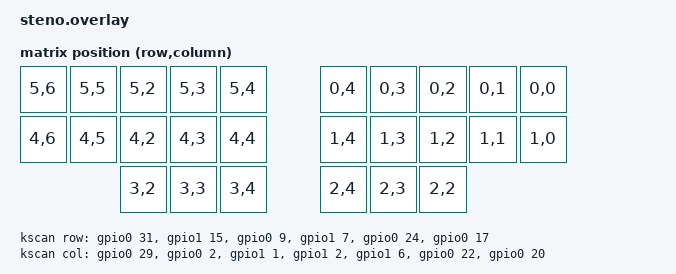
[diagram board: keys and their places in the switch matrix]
// This file was generated from a template. Edit it to match your keyboard.
// See https://zmk.dev/docs/development/hardware-integration/new-shield for more
// instructions.

#include <dt-bindings/zmk/matrix_transform.h>

#include "steno-layouts.dtsi"

/ {
    chosen {
        zmk,physical-layout = &default_layout;
    };

    kscan: kscan {
        // If the hardware does not use a switch matrix, change this to the
        // appropriate driver and update the properties below to match.
        // See https://zmk.dev/docs/config/kscan for supported key scan drivers.
        compatible = "zmk,kscan-gpio-matrix";
        // Set this to "col2row" or "row2col" to match the hardware. If using
        // "row2col", change the col-gpios to (GPIO_ACTIVE_HIGH | GPIO_PULL_DOWN)
        // and the row-gpios to GPIO_ACTIVE_HIGH.
        diode-direction = "col2row";
        wakeup-source;

        // Replace these comments with the GPIO pins in the matrix.
        // See https://zmk.dev/docs/development/hardware-integration/new-shield#shield-overlays
        col-gpios
            = <&gpio0 29 GPIO_ACTIVE_HIGH>
            , <&gpio0 2 GPIO_ACTIVE_HIGH>
            , <&gpio1 1 GPIO_ACTIVE_HIGH>
            , <&gpio1 2 GPIO_ACTIVE_HIGH>
            , <&gpio1 6 GPIO_ACTIVE_HIGH>
            , <&gpio0 22 GPIO_ACTIVE_HIGH>
            , <&gpio0 20 GPIO_ACTIVE_HIGH>
            ;

        row-gpios
            = <&gpio0 31 (GPIO_ACTIVE_HIGH | GPIO_PULL_DOWN)>
            , <&gpio1 15 (GPIO_ACTIVE_HIGH | GPIO_PULL_DOWN)>
            , <&gpio0 9 (GPIO_ACTIVE_HIGH | GPIO_PULL_DOWN)>
            , <&gpio1 7 (GPIO_ACTIVE_HIGH | GPIO_PULL_DOWN)>
            , <&gpio0 24 (GPIO_ACTIVE_HIGH | GPIO_PULL_DOWN)>
            , <&gpio0 17 (GPIO_ACTIVE_HIGH | GPIO_PULL_DOWN)>
            ;
    };

    default_transform: default_transform {
        // See https://zmk.dev/docs/development/hardware-integration/new-shield#matrix-transform
        // for how to configure this
        compatible = "zmk,matrix-transform";
        columns = <6>;
        rows = <7>;

        map = <
            RC(5,6) RC(5,5) RC(5,2) RC(5,3) RC(5,4) RC(0,4) RC(0,3) RC(0,2) RC(0,1) RC(0,0)
            RC(4,6) RC(4,5) RC(4,2) RC(4,3) RC(4,4) RC(1,4) RC(1,3) RC(1,2) RC(1,1) RC(1,0)
                            RC(3,2) RC(3,3) RC(3,4) RC(2,4) RC(2,3) RC(2,2)
        >;
    };
};
